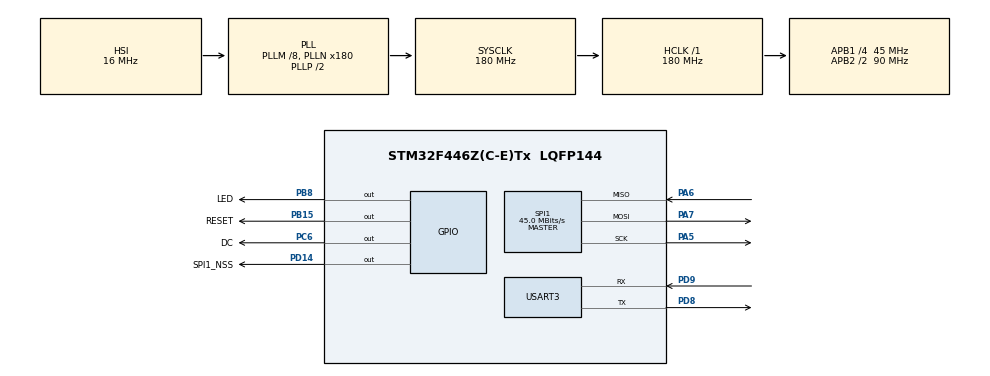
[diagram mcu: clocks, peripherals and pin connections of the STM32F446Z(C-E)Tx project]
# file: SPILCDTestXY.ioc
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Dma.Request0=SPI1_TX
Dma.SPI1_TX.0.Direction=DMA_MEMORY_TO_PERIPH
Dma.SPI1_TX.0.FIFOMode=DMA_FIFOMODE_DISABLE
Dma.SPI1_TX.0.Instance=DMA2_Stream3
Dma.SPI1_TX.0.MemDataAlignment=DMA_MDATAALIGN_BYTE
Dma.SPI1_TX.0.MemInc=DMA_MINC_ENABLE
Dma.SPI1_TX.0.Mode=DMA_NORMAL
Dma.SPI1_TX.0.PeriphDataAlignment=DMA_PDATAALIGN_BYTE
Dma.SPI1_TX.0.PeriphInc=DMA_PINC_DISABLE
Dma.SPI1_TX.0.Priority=DMA_PRIORITY_LOW
Mcu.Family=STM32F4
Mcu.Name=STM32F446Z(C-E)Tx
Mcu.Package=LQFP144
NVIC.DMA2_Stream3_IRQn=true\:1\:0\:true\:false\:true\:false\:true
NVIC.PriorityGroup=NVIC_PRIORITYGROUP_4
NVIC.TIM2_IRQn=true\:2\:0\:true\:false\:true\:true\:true
NVIC.USART3_IRQn=true\:3\:0\:true\:false\:true\:true\:true
PA5.GPIO_PuPd=GPIO_PULLDOWN
PA5.Mode=Full_Duplex_Master
PA5.Signal=SPI1_SCK
PA6.GPIO_PuPd=GPIO_PULLDOWN
PA6.Mode=Full_Duplex_Master
PA6.Signal=SPI1_MISO
PA7.GPIO_PuPd=GPIO_PULLDOWN
PA7.Mode=Full_Duplex_Master
PA7.Signal=SPI1_MOSI
PB15.GPIO_Label=RESET
PB15.GPIO_PuPd=GPIO_PULLUP
PB15.GPIO_Speed=GPIO_SPEED_FREQ_VERY_HIGH
PB15.PinState=GPIO_PIN_SET
PB15.Signal=GPIO_Output
PB8.GPIO_Label=LED
PB8.GPIO_PuPd=GPIO_PULLUP
PB8.GPIO_Speed=GPIO_SPEED_FREQ_VERY_HIGH
PB8.PinState=GPIO_PIN_SET
PB8.Signal=GPIO_Output
PC6.GPIO_Label=DC
PC6.GPIO_PuPd=GPIO_PULLUP
PC6.GPIO_Speed=GPIO_SPEED_FREQ_VERY_HIGH
PC6.PinState=GPIO_PIN_SET
PC6.Signal=GPIO_Output
PD14.GPIO_Label=SPI1_NSS
PD14.GPIO_PuPd=GPIO_PULLUP
PD14.GPIO_Speed=GPIO_SPEED_FREQ_VERY_HIGH
PD14.PinState=GPIO_PIN_SET
PD14.Signal=GPIO_Output
PD8.Mode=Asynchronous
PD8.Signal=USART3_TX
PD9.Mode=Asynchronous
PD9.Signal=USART3_RX
ProjectManager.HeapSize=0x200
ProjectManager.StackSize=0x400
ProjectManager.TargetToolchain=STM32CubeIDE
RCC.AHBFreq_Value=180000000
RCC.APB1CLKDivider=RCC_HCLK_DIV4
RCC.APB1Freq_Value=45000000
RCC.APB1TimFreq_Value=90000000
RCC.APB2CLKDivider=RCC_HCLK_DIV2
RCC.APB2Freq_Value=90000000
RCC.APB2TimFreq_Value=180000000
RCC.CortexFreq_Value=180000000
RCC.HCLKFreq_Value=180000000
RCC.PLLM=8
RCC.PLLN=180
RCC.SYSCLKFreq_VALUE=180000000
RCC.SYSCLKSource=RCC_SYSCLKSOURCE_PLLCLK
RCC.USBFreq_Value=180000000
RCC.VCOOutputFreq_Value=360000000
SPI1.BaudRatePrescaler=SPI_BAUDRATEPRESCALER_2
SPI1.CalculateBaudRate=45.0 MBits/s
SPI1.Direction=SPI_DIRECTION_2LINES
SPI1.Mode=SPI_MODE_MASTER
SPI1.VirtualType=VM_MASTER
TIM2.AutoReloadPreload=TIM_AUTORELOAD_PRELOAD_ENABLE
TIM2.Period=4999
TIM2.Prescaler=44999
USART3.VirtualMode=VM_ASYNC
VP_TIM2_VS_ClockSourceINT.Mode=Internal
board=custom

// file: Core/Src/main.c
/* USER CODE BEGIN Header */
/**
  ******************************************************************************
  * @file           : main.c
  * @brief          : Main program body
  ******************************************************************************
  * @attention
  *
  * <h2><center>&copy; Copyright (c) 2019 STMicroelectronics.
  * All rights reserved.</center></h2>
  *
  * This software component is licensed by ST under BSD 3-Clause license,
  * the "License"; You may not use this file except in compliance with the
  * License. You may obtain a copy of the License at:
  *                        opensource.org/licenses/BSD-3-Clause
  *
  ******************************************************************************
  */
/* USER CODE END Header */

#include "main.h"

/* USER CODE BEGIN Includes */
#include "ili9341.h"
#include "gui.h"
#include <stdio.h>
#include <string.h>
/* USER CODE END Includes */

SPI_HandleTypeDef hspi1;
DMA_HandleTypeDef hdma_spi1_tx;

TIM_HandleTypeDef htim2;

UART_HandleTypeDef huart3;

void SystemClock_Config(void);
static void MX_GPIO_Init(void);
static void MX_DMA_Init(void);
static void MX_SPI1_Init(void);
static void MX_TIM2_Init(void);
static void MX_USART3_UART_Init(void);

int main(void)
{

  /* MCU Configuration--------------------------------------------------------*/

  /* Reset of all peripherals, Initializes the Flash interface and the Systick. */
  HAL_Init();

  /* Configure the system clock */
  SystemClock_Config();

  /* Initialize all configured peripherals */
  MX_GPIO_Init();
  MX_DMA_Init();
  MX_SPI1_Init();
  MX_TIM2_Init();
  MX_USART3_UART_Init();
  /* USER CODE BEGIN 2 */
  ILI9341_Init();
  GUI_FillScreen(BLACK);
  for (uint16_t xy = 0; xy < GUI_HEIGHT; xy++) {
	  GUI_WritePixel(xy, xy, WHITE);
  }
  /* USER CODE END 2 */

  /* Infinite loop */
  while (1)
  {

  }
}

void SystemClock_Config(void)
{
  RCC_OscInitTypeDef RCC_OscInitStruct = {0};
  RCC_ClkInitTypeDef RCC_ClkInitStruct = {0};

  /** Configure the main internal regulator output voltage
  */
  __HAL_RCC_PWR_CLK_ENABLE();
  __HAL_PWR_VOLTAGESCALING_CONFIG(PWR_REGULATOR_VOLTAGE_SCALE1);
  /** Initializes the CPU, AHB and APB busses clocks
  */
  RCC_OscInitStruct.OscillatorType = RCC_OSCILLATORTYPE_HSI;
  RCC_OscInitStruct.HSIState = RCC_HSI_ON;
  RCC_OscInitStruct.HSICalibrationValue = RCC_HSICALIBRATION_DEFAULT;
  RCC_OscInitStruct.PLL.PLLState = RCC_PLL_ON;
  RCC_OscInitStruct.PLL.PLLSource = RCC_PLLSOURCE_HSI;
  RCC_OscInitStruct.PLL.PLLM = 8;
  RCC_OscInitStruct.PLL.PLLN = 180;
  RCC_OscInitStruct.PLL.PLLP = RCC_PLLP_DIV2;
  RCC_OscInitStruct.PLL.PLLQ = 2;
  RCC_OscInitStruct.PLL.PLLR = 2;
  if (HAL_RCC_OscConfig(&RCC_OscInitStruct) != HAL_OK)
  {
    Error_Handler();
  }
  /** Activate the Over-Drive mode
  */
  if (HAL_PWREx_EnableOverDrive() != HAL_OK)
  {
    Error_Handler();
  }
  /** Initializes the CPU, AHB and APB busses clocks
  */
  RCC_ClkInitStruct.ClockType = RCC_CLOCKTYPE_HCLK|RCC_CLOCKTYPE_SYSCLK
                              |RCC_CLOCKTYPE_PCLK1|RCC_CLOCKTYPE_PCLK2;
  RCC_ClkInitStruct.SYSCLKSource = RCC_SYSCLKSOURCE_PLLCLK;
  RCC_ClkInitStruct.AHBCLKDivider = RCC_SYSCLK_DIV1;
  RCC_ClkInitStruct.APB1CLKDivider = RCC_HCLK_DIV4;
  RCC_ClkInitStruct.APB2CLKDivider = RCC_HCLK_DIV2;

  if (HAL_RCC_ClockConfig(&RCC_ClkInitStruct, FLASH_LATENCY_5) != HAL_OK)
  {
    Error_Handler();
  }
}

static void MX_SPI1_Init(void)
{

  /* SPI1 parameter configuration*/
  hspi1.Instance = SPI1;
  hspi1.Init.Mode = SPI_MODE_MASTER;
  hspi1.Init.Direction = SPI_DIRECTION_2LINES;
  hspi1.Init.DataSize = SPI_DATASIZE_8BIT;
  hspi1.Init.CLKPolarity = SPI_POLARITY_LOW;
  hspi1.Init.CLKPhase = SPI_PHASE_1EDGE;
  hspi1.Init.NSS = SPI_NSS_SOFT;
  hspi1.Init.BaudRatePrescaler = SPI_BAUDRATEPRESCALER_2;
  hspi1.Init.FirstBit = SPI_FIRSTBIT_MSB;
  hspi1.Init.TIMode = SPI_TIMODE_DISABLE;
  hspi1.Init.CRCCalculation = SPI_CRCCALCULATION_DISABLE;
  hspi1.Init.CRCPolynomial = 10;
  if (HAL_SPI_Init(&hspi1) != HAL_OK)
  {
    Error_Handler();
  }

}

static void MX_TIM2_Init(void)
{

  TIM_ClockConfigTypeDef sClockSourceConfig = {0};
  TIM_MasterConfigTypeDef sMasterConfig = {0};

  htim2.Instance = TIM2;
  htim2.Init.Prescaler = 44999;
  htim2.Init.CounterMode = TIM_COUNTERMODE_UP;
  htim2.Init.Period = 4999;
  htim2.Init.ClockDivision = TIM_CLOCKDIVISION_DIV1;
  htim2.Init.AutoReloadPreload = TIM_AUTORELOAD_PRELOAD_ENABLE;
  if (HAL_TIM_Base_Init(&htim2) != HAL_OK)
  {
    Error_Handler();
  }
  sClockSourceConfig.ClockSource = TIM_CLOCKSOURCE_INTERNAL;
  if (HAL_TIM_ConfigClockSource(&htim2, &sClockSourceConfig) != HAL_OK)
  {
    Error_Handler();
  }
  sMasterConfig.MasterOutputTrigger = TIM_TRGO_RESET;
  sMasterConfig.MasterSlaveMode = TIM_MASTERSLAVEMODE_DISABLE;
  if (HAL_TIMEx_MasterConfigSynchronization(&htim2, &sMasterConfig) != HAL_OK)
  {
    Error_Handler();
  }

}

static void MX_USART3_UART_Init(void)
{

  huart3.Instance = USART3;
  huart3.Init.BaudRate = 115200;
  huart3.Init.WordLength = UART_WORDLENGTH_8B;
  huart3.Init.StopBits = UART_STOPBITS_1;
  huart3.Init.Parity = UART_PARITY_NONE;
  huart3.Init.Mode = UART_MODE_TX_RX;
  huart3.Init.HwFlowCtl = UART_HWCONTROL_NONE;
  huart3.Init.OverSampling = UART_OVERSAMPLING_16;
  if (HAL_UART_Init(&huart3) != HAL_OK)
  {
    Error_Handler();
  }

}

static void MX_DMA_Init(void)
{

  /* DMA controller clock enable */
  __HAL_RCC_DMA2_CLK_ENABLE();

  /* DMA interrupt init */
  /* DMA2_Stream3_IRQn interrupt configuration */
  HAL_NVIC_SetPriority(DMA2_Stream3_IRQn, 1, 0);
  HAL_NVIC_EnableIRQ(DMA2_Stream3_IRQn);

}

static void MX_GPIO_Init(void)
{
  GPIO_InitTypeDef GPIO_InitStruct = {0};

  /* GPIO Ports Clock Enable */
  __HAL_RCC_GPIOA_CLK_ENABLE();
  __HAL_RCC_GPIOB_CLK_ENABLE();
  __HAL_RCC_GPIOD_CLK_ENABLE();
  __HAL_RCC_GPIOC_CLK_ENABLE();

  /*Configure GPIO pin Output Level */
  HAL_GPIO_WritePin(GPIOB, RESET_Pin|LED_Pin, GPIO_PIN_SET);

  /*Configure GPIO pin Output Level */
  HAL_GPIO_WritePin(SPI1_NSS_GPIO_Port, SPI1_NSS_Pin, GPIO_PIN_SET);

  /*Configure GPIO pin Output Level */
  HAL_GPIO_WritePin(DC_GPIO_Port, DC_Pin, GPIO_PIN_SET);

  /*Configure GPIO pins : RESET_Pin LED_Pin */
  GPIO_InitStruct.Pin = RESET_Pin|LED_Pin;
  GPIO_InitStruct.Mode = GPIO_MODE_OUTPUT_PP;
  GPIO_InitStruct.Pull = GPIO_PULLUP;
  GPIO_InitStruct.Speed = GPIO_SPEED_FREQ_VERY_HIGH;
  HAL_GPIO_Init(GPIOB, &GPIO_InitStruct);

  /*Configure GPIO pin : SPI1_NSS_Pin */
  GPIO_InitStruct.Pin = SPI1_NSS_Pin;
  GPIO_InitStruct.Mode = GPIO_MODE_OUTPUT_PP;
  GPIO_InitStruct.Pull = GPIO_PULLUP;
  GPIO_InitStruct.Speed = GPIO_SPEED_FREQ_VERY_HIGH;
  HAL_GPIO_Init(SPI1_NSS_GPIO_Port, &GPIO_InitStruct);

  /*Configure GPIO pin : DC_Pin */
  GPIO_InitStruct.Pin = DC_Pin;
  GPIO_InitStruct.Mode = GPIO_MODE_OUTPUT_PP;
  GPIO_InitStruct.Pull = GPIO_PULLUP;
  GPIO_InitStruct.Speed = GPIO_SPEED_FREQ_VERY_HIGH;
  HAL_GPIO_Init(DC_GPIO_Port, &GPIO_InitStruct);

}

void Error_Handler(void)
{
  /* USER CODE BEGIN Error_Handler_Debug */
  /* User can add his own implementation to report the HAL error return state */
	while (1)
		;
  /* USER CODE END Error_Handler_Debug */
}

/************************ (C) COPYRIGHT STMicroelectronics *****END OF FILE****/
